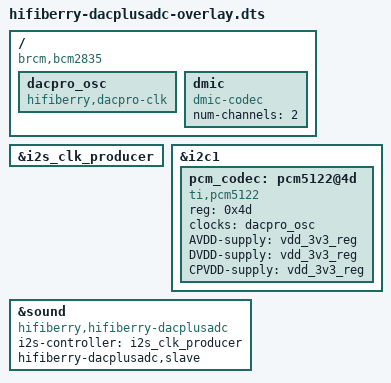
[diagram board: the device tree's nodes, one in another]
// Definitions for HiFiBerry DAC+ADC, no onboard clocks
/dts-v1/;
/plugin/;

/ {
	compatible = "brcm,bcm2835";

	fragment@0 {
		target-path = "/";
		__overlay__ {
			dacpro_osc: dacpro_osc {
				compatible = "hifiberry,dacpro-clk";
				#clock-cells = <0>;
			};
		};
	};

	fragment@1 {
		target = <&i2s_clk_producer>;
		__overlay__ {
			status = "okay";
		};
	};

	fragment@2 {
		target = <&i2c1>;
		__overlay__ {
			#address-cells = <1>;
			#size-cells = <0>;
			status = "okay";

			pcm_codec: pcm5122@4d {
				#sound-dai-cells = <0>;
				compatible = "ti,pcm5122";
				reg = <0x4d>;
				clocks = <&dacpro_osc>;
				AVDD-supply = <&vdd_3v3_reg>;
				DVDD-supply = <&vdd_3v3_reg>;
				CPVDD-supply = <&vdd_3v3_reg>;
				status = "okay";
			};
		};
	};

	fragment@3 {
		target-path = "/";
		__overlay__ {
			dmic {
				#sound-dai-cells = <0>;
				compatible = "dmic-codec";
				num-channels = <2>;
				status = "okay";
			};
		};
	};

	fragment@4 {
		target = <&sound>;
		hifiberry_dacplusadc: __overlay__ {
			compatible = "hifiberry,hifiberry-dacplusadc";
			i2s-controller = <&i2s_clk_producer>;
			hifiberry-dacplusadc,slave;
			status = "okay";
		};
	};

	__overrides__ {
		24db_digital_gain =
			<&hifiberry_dacplusadc>,"hifiberry,24db_digital_gain?";
		leds_off = <&hifiberry_dacplusadc>,"hifiberry-dacplusadc,leds_off?";
	};
};
